# LPC54102_cm0plus register map
Vendor: nxp.com; File version: 1.0
CPU: CM0PLUS r0p0, little endian, no MPU, no FPU, VTOR, 2 interrupt priority bits
Registers are 32-bit, read-write, reset 0x0 unless marked. A register's access mark holds for its fields unless they carry their own. Offsets are from the block's base; [hi:lo] are bit positions; lines under a group give offsets from that group; {n}, {i} and the like mark numbered series.

## MAILBOX — LPC5410x Mailbox
Base 0x1C02C000
{0x0+0x10*i} MBOXIRQ[{i}] (i=0..1) group
  0x00 IRQ — Interrupt request register for the Cortex-M0+ CPU.
    [31:0] INTREQ — If any bit is set, an interrupt request is sent to the Cortex-M0+ interrupt controller.
  0x04 IRQSET wo reset not defined — Set bits in IRQ0
    [31:0] INTREQSET — Writing 1 sets the corresponding bit in the IRQ0 register.
  0x08 IRQCLR wo reset not defined — Clear bits in IRQ0
    [31:0] INTREQCLR — Writing 1 clears the corresponding bit in the IRQ0 register.
0xF8 MUTEX reset 0x1 — Mutual exclusion register[1]
  [0] EX — Cleared when read, set when written. See usage description above.

## GINT0 — LPC5410x Group GPIO input interrupt (GINT0/1)
Base 0x40010000
Same registers: GINT1 0x40014000
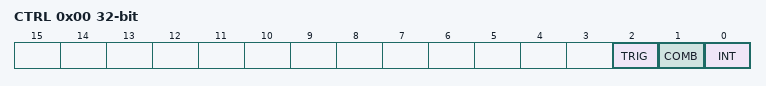
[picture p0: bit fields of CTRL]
0x00 CTRL — GPIO grouped interrupt control register
  [2] TRIG — Group interrupt trigger
    0=EDGE_TRIGGERED; 1=LEVEL_TRIGGERED
  [1] COMB — Combine enabled inputs for group interrupt
    0=OR (Or. OR functionality: A grouped interrupt is generated when any one of the enabled inputs is active (based on its programmed polarity).); 1=AND (And. AND functionality: An interrupt is generated when all enabled bits are active (based on their programmed polarity).)
  [0] INT — Group interrupt status. This bit is cleared by writing a one to it. Writing zero has no effect.
    0=NO_REQUEST (No request. No interrupt request is pending.); 1=REQUEST_ACTIVE (Request active. Interrupt request is active.)
{0x20+4i} PORT_POL[{i}] (i=0..1) reset 0xFFFFFFFF — GPIO grouped interrupt port 0 polarity register
  [31:0] POL — Configure pin polarity of port m pins for group interrupt. Bit n corresponds to pin PIOm_n of port m. 0 = the pin is active LOW. If the level on this pin is LOW, the pin contributes to the group interrupt. 1 = the pin is active HIGH. If the level on this pin is HIGH, the pin contributes to the group interrupt.
{0x40+4i} PORT_ENA[{i}] (i=0..1) — GPIO grouped interrupt port 0 enable register
  [31:0] ENA — Enable port 0 pin for group interrupt. Bit n corresponds to pin Pm_n of port m. 0 = the port 0 pin is disabled and does not contribute to the grouped interrupt. 1 = the port 0 pin is enabled and contributes to the grouped interrupt.

## UTICK0 — LPC5410x Micro-tick Timer (UTICK)
Base 0x40020000
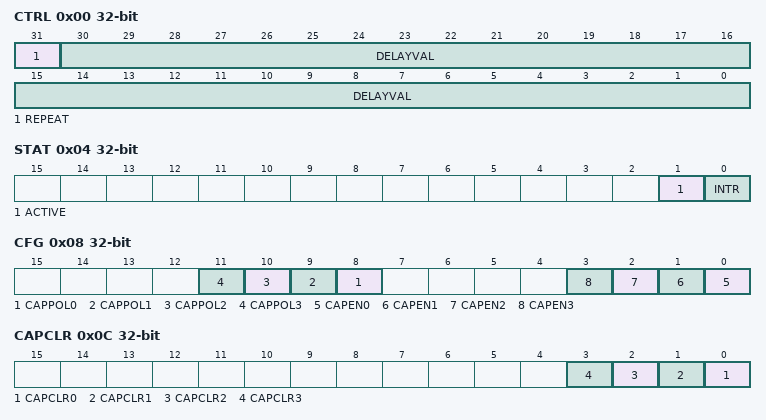
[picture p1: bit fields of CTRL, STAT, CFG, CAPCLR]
0x00 CTRL — Control register.
  [31] REPEAT — Repeat delay. 0 = One-time delay. 1 = Delay repeats continuously.
  [30:0] DELAYVAL — Tick interval value. The delay will be equal to DELAYVAL + 1 periods of the timer clock. The minimum usable value is 1, for a delay of 2 timer clocks. A value of 0 stops the timer.
0x04 STAT — Status register.
  [1] ACTIVE — Active flag. 0 = The Micro-Tick Timer is stopped. 1 = The Micro-Tick Timer is currently active.
  [0] INTR — Interrupt flag. 0 = No interrupt is pending. 1 = An interrupt is pending. A write of any value to this register clears this flag.
0x08 CFG — Capture configuration register.
  [n+8] CAPPOL{n} (n=0..3) — Capture Polarity {n}. 0 = Positive edge capture, 1 = Negative edge capture.
  [n] CAPEN{n} (n=0..3) — Enable Capture {n}. 1 = Enabled, 0 = Disabled.
0x0C CAPCLR wo reset not defined — Capture clear register.
  [n] CAPCLR{n} (n=0..3) — Clear capture {n}. Writing 1 to this bit clears the CAP{n} register value.
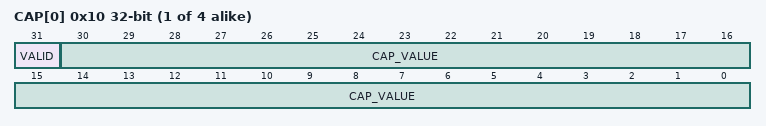
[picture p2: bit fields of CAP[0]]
{0x10+4i} CAP[{i}] (i=0..3) ro — Capture register .
  [31] VALID — Capture Valid. When 1, a value has been captured based on a transition of the related UTICK_CAPn pin. Cleared by writing to the related bit in the CAPCLR register.
  [30:0] CAP_VALUE — Capture value for the related capture event (UTICK_CAPn. Note: the value is 1 lower than the actual value of the Micro-tick Timer at the moment of the capture event.
